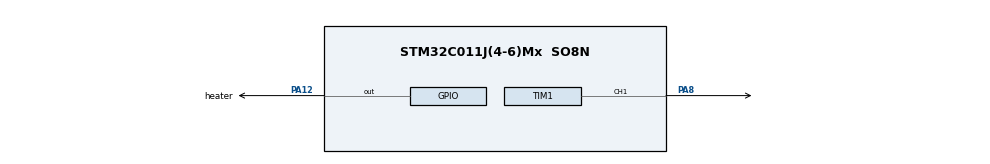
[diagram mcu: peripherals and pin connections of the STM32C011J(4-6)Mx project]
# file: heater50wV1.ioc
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Mcu.Family=STM32C0
Mcu.Name=STM32C011J(4-6)Mx
Mcu.Package=SO8N
NVIC.FLASH_IRQn=true\:0\:0\:false\:false\:true\:true\:true\:true
PA12\ [PA10].GPIO_Label=heater
PA12\ [PA10].GPIO_ModeDefaultOutputPP=GPIO_MODE_OUTPUT_PP
PA12\ [PA10].GPIO_PuPd=GPIO_NOPULL
PA12\ [PA10].GPIO_Speed=GPIO_SPEED_FREQ_VERY_HIGH
PA12\ [PA10].PinState=GPIO_PIN_SET
PA12\ [PA10].Signal=GPIO_Output
PA8.Signal=S_TIM1_CH1
PA8__PA11\ [PA9].StandardMode=true
PC14-OSCX_IN\ (PC14)__PB7.StandardMode=true
PC15-OSCX_OUT\ (PC15)__PA14-BOOT0__PB6.StandardMode=true
PF2-NRST__PA0__PA1__PA2.StandardMode=true
ProjectManager.HeapSize=0x200
ProjectManager.StackSize=0x400
ProjectManager.TargetToolchain=STM32CubeIDE
RCC.ADCFreq_Value=48000000
RCC.AHBFreq_Value=48000000
RCC.CortexFreq_Value=48000000
RCC.EXTERNAL_CLOCK_VALUE=12288000
RCC.HCLKFreq_Value=48000000
RCC.HSE_VALUE=8000000
RCC.HSISYSCLKDivider=RCC_HSI_DIV1
RCC.HSI_VALUE=48000000
RCC.LSE_VALUE=32768
RCC.SYSCLKFreq_VALUE=48000000
SH.S_TIM1_CH1.0=TIM1_CH1,PWM Generation1 CH1
TIM1.Channel-PWM\ Generation1\ CH1=TIM_CHANNEL_1
TIM1.Period=1004
TIM1.Prescaler=47
TIM1.Pulse-PWM\ Generation1\ CH1=502
VP_TIM1_VS_ClockSourceINT.Mode=Internal
board=custom

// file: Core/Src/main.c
/* USER CODE BEGIN Header */
/**
  ******************************************************************************
  * @file           : main.c
  * @brief          : Main program body
  ******************************************************************************
  * @attention
  *
  * Copyright (c) 2025 STMicroelectronics.
  * All rights reserved.
  *
  * This software is licensed under terms that can be found in the LICENSE file
  * in the root directory of this software component.
  * If no LICENSE file comes with this software, it is provided AS-IS.
  *
  ******************************************************************************
  */
/* USER CODE END Header */
#include "main.h"
#include "tim.h"
#include "gpio.h"

/* USER CODE BEGIN Includes */

#include "stdio.h"
#include "math.h"
#include "stm32c0xx_ll_bus.h"
#include "stm32c0xx_hal.h"
/* USER CODE END Includes */

/* USER CODE BEGIN PD */
//VARIABLE FOR AD CONVERSION

/* USER CODE END PD */

void SystemClock_Config(void);

/* USER CODE BEGIN 0 */
uint8_t nothing(void){
	uint8_t i=0;
	while(i<10){
		i++;
	}
	return(i);

}

/* USER CODE END 0 */

int main(void)
{

  /* MCU Configuration--------------------------------------------------------*/

  /* Reset of all peripherals, Initializes the Flash interface and the Systick. */
  HAL_Init();

  /* Configure the system clock */
  SystemClock_Config();

  /* Initialize all configured peripherals */
  MX_GPIO_Init();
  MX_TIM1_Init();
  /* USER CODE BEGIN 2 */
  HAL_TIM_PWM_Start(&htim1, TIM_CHANNEL_1);

  /* USER CODE END 2 */

  /* Infinite loop */
  /* USER CODE BEGIN WHILE */
  while (1)
  {

	  //HEATER_PIN_ON;
	  LL_mDelay(1);
	  //HEATER_PIN_OFF;
	  LL_mDelay(1);

    /* USER CODE END WHILE */

  }
}

void SystemClock_Config(void)
{

  LL_FLASH_SetLatency(LL_FLASH_LATENCY_1);

  /* HSI configuration and activation */
  LL_RCC_HSI_Enable();
  while(LL_RCC_HSI_IsReady() != 1)
  {
  }

  LL_RCC_HSI_SetCalibTrimming(64);
  LL_RCC_SetHSIDiv(LL_RCC_HSI_DIV_1);
  /* Set AHB prescaler*/
  LL_RCC_SetAHBPrescaler(LL_RCC_HCLK_DIV_1);

  /* Sysclk activation on the HSI */
  LL_RCC_SetSysClkSource(LL_RCC_SYS_CLKSOURCE_HSI);
  while(LL_RCC_GetSysClkSource() != LL_RCC_SYS_CLKSOURCE_STATUS_HSI)
  {
  }

  /* Set APB1 prescaler*/
  LL_RCC_SetAPB1Prescaler(LL_RCC_APB1_DIV_1);
  /* Update CMSIS variable (which can be updated also through SystemCoreClockUpdate function) */
  LL_SetSystemCoreClock(48000000);

   /* Update the time base */
  if (HAL_InitTick (TICK_INT_PRIORITY) != HAL_OK)
  {
    Error_Handler();
  }
}

void Error_Handler(void)
{
  __disable_irq();
  while (1)
  {
  }
}
